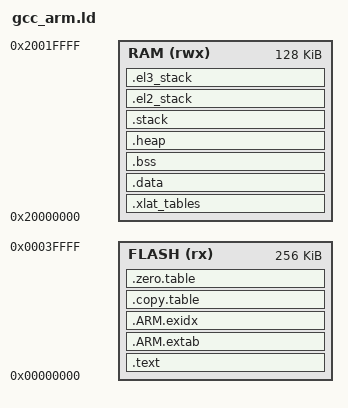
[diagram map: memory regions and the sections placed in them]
/******************************************************************************
 * @file     gcc_arm.ld
 * @brief    GNU Linker Script for Cortex-A based device
 * @version  V1.0.1
 * @date     20. August 2020
 ******************************************************************************/
/*
 * Copyright (c) 2020 Arm Limited. All rights reserved.
 *
 * SPDX-License-Identifier: Apache-2.0
 *
 * Licensed under the Apache License, Version 2.0 (the License); you may
 * not use this file except in compliance with the License.
 * You may obtain a copy of the License at
 *
 * www.apache.org/licenses/LICENSE-2.0
 *
 * Unless required by applicable law or agreed to in writing, software
 * distributed under the License is distributed on an AS IS BASIS, WITHOUT
 * WARRANTIES OR CONDITIONS OF ANY KIND, either express or implied.
 * See the License for the specific language governing permissions and
 * limitations under the License.
 */

/*
 *-------- <<< Use Configuration Wizard in Context Menu >>> -------------------
 */

/*---------------------- Flash Configuration ----------------------------------
  <h> Flash Configuration
    <o0> Flash Base Address <0x0-0xFFFFFFFF:8>
    <o1> Flash Size (in Bytes) <0x0-0xFFFFFFFF:8>
  </h>
  -----------------------------------------------------------------------------*/
__ROM_BASE = 0x00000000;
__ROM_SIZE = 0x00040000;

/*--------------------- Embedded RAM Configuration ----------------------------
  <h> RAM Configuration
    <o0> RAM Base Address    <0x0-0xFFFFFFFF:8>
    <o1> RAM Size (in Bytes) <0x0-0xFFFFFFFF:8>
  </h>
 -----------------------------------------------------------------------------*/
__RAM_BASE = 0x20000000;
__RAM_SIZE = 0x00020000;

/*--------------------- Stack / Heap Configuration ----------------------------
  <h> Stack / Heap Configuration
    <o0> Stack Size (in Bytes) <0x0-0xFFFFFFFF:8>
    <o1> Heap Size (in Bytes) <0x0-0xFFFFFFFF:8>
  </h>
  -----------------------------------------------------------------------------*/
__STACK_SIZE = 0x00004000;
__HEAP_SIZE  = 0x0000C000;

/*--------------------- EL2 Stack Configuration -------------------------------
  <h> EL2 Stack Configuration
    <o0> Stack Size (in Bytes) <0x0-0xFFFFFFFF:8>
  </h>
 -----------------------------------------------------------------------------*/
__EL2_STACK_SIZE = 0x00004000;

/*--------------------- EL3 Stack Configuration -------------------------------
  <h> EL3 Stack Configuration
    <o0> Stack Size (in Bytes) <0x0-0xFFFFFFFF:8>
  </h>
  -----------------------------------------------------------------------------*/
__EL3_STACK_SIZE = 0x00004000;

/*
 *-------------------- <<< end of configuration section >>> -------------------
 */

MEMORY
{
  FLASH (rx)  : ORIGIN = __ROM_BASE, LENGTH = __ROM_SIZE
  RAM   (rwx) : ORIGIN = __RAM_BASE, LENGTH = __RAM_SIZE
}

/* Linker script to place sections and symbol values. Should be used together
 * with other linker script that defines memory regions FLASH and RAM.
 * It references following symbols, which must be defined in code:
 *   Reset_Handler : Entry of reset handler
 *
 * It defines following symbols, which code can use without definition:
 *   __exidx_start
 *   __exidx_end
 *   __copy_table_start__
 *   __copy_table_end__
 *   __zero_table_start__
 *   __zero_table_end__
 *   __etext
 *   __data_start__
 *   __preinit_array_start
 *   __preinit_array_end
 *   __init_array_start
 *   __init_array_end
 *   __fini_array_start
 *   __fini_array_end
 *   __data_end__
 *   __bss_start__
 *   __bss_end__
 *   __end__
 *   end
 *   __HeapLimit
 *   __StackLimit
 *   __StackTop
 *   __stack
 */
ENTRY(Reset_Handler)

SECTIONS
{
  .text :
  {
    KEEP(*(.startup))

    KEEP(*(.vectors))
    *(.text*)

    KEEP(*(.init))
    KEEP(*(.fini))

    /* .ctors */
    *crtbegin.o(.ctors)
    *crtbegin?.o(.ctors)
    *(EXCLUDE_FILE(*crtend?.o *crtend.o) .ctors)
    *(SORT(.ctors.*))
    *(.ctors)

    /* .dtors */
    *crtbegin.o(.dtors)
    *crtbegin?.o(.dtors)
    *(EXCLUDE_FILE(*crtend?.o *crtend.o) .dtors)
    *(SORT(.dtors.*))
    *(.dtors)

    *(.rodata*)
    *(.gcc_except_table*)

    KEEP(*(.eh_frame*))
  } > FLASH

  /*
   * SG veneers:
   * All SG veneers are placed in the special output section .gnu.sgstubs. Its start address
   * must be set, either with the command line option ?--section-start? or in a linker script,
   * to indicate where to place these veneers in memory.
   */
/*
  .gnu.sgstubs :
  {
    . = ALIGN(32);
  } > FLASH
*/

  .ARM.extab :
  {
    *(.ARM.extab* .gnu.linkonce.armextab.*)
  } > FLASH

  __exidx_start = .;
  .ARM.exidx :
  {
    *(.ARM.exidx* .gnu.linkonce.armexidx.*)
  } > FLASH
  __exidx_end = .;

  .copy.table :
  {
    . = ALIGN(8);
    __copy_table_start__ = .;
    LONG (__etext)
    LONG (__data_start__)
    LONG ((__data_end__ - __data_start__) / 4)
    /* Add each additional data section here */
/*
    LONG (__etext2)
    LONG (__data2_start__)
    LONG ((__data2_end__ - __data2_start__) / 4)
*/
    __copy_table_end__ = .;
  } > FLASH

  .zero.table :
  {
    . = ALIGN(8);
    __zero_table_start__ = .;
    /* Add each additional bss section here */
/*
    LONG (__bss2_start__)
    LONG ((__bss2_end__ - __bss2_start__) / 4)
*/
    __zero_table_end__ = .;
  } > FLASH

  .xlat_tables :
  {
    . = ALIGN(4096);
    *(.xlat_tables)
 } > RAM

  __etext = ALIGN (8);

  .data : AT (__etext)
  {
    __data_start__ = .;
    *(vtable)
    *(.data)
    *(.data.*)

    . = ALIGN(8);
    /* preinit data */
    PROVIDE_HIDDEN (__preinit_array_start = .);
    KEEP(*(.preinit_array))
    PROVIDE_HIDDEN (__preinit_array_end = .);

    . = ALIGN(8);
    /* init data */
    PROVIDE_HIDDEN (__init_array_start = .);
    KEEP(*(SORT(.init_array.*)))
    KEEP(*(.init_array))
    PROVIDE_HIDDEN (__init_array_end = .);

    . = ALIGN(8);
    /* finit data */
    PROVIDE_HIDDEN (__fini_array_start = .);
    KEEP(*(SORT(.fini_array.*)))
    KEEP(*(.fini_array))
    PROVIDE_HIDDEN (__fini_array_end = .);

    KEEP(*(.jcr*))
    . = ALIGN(8);
    /* All data end */
    __data_end__ = .;

  } > RAM

  /*
   * Secondary data section, optional
   *
   * Remember to add each additional data section
   * to the .copy.table  and .ecc.table above to asure proper
   * initialization during startup.
   */
/*
  __etext2 = ALIGN (8);

  .data2 : AT (__etext2)
  {
    . = ALIGN(8);
    __data2_start__ = .;
    *(.data2)
    *(.data2.*)
    . = ALIGN(8);
    __data2_end__ = .;
  } > RAM2
*/

  .bss :
  {
    . = ALIGN(8);
    __bss_start__ = .;
    *(.bss)
    *(.bss.*)
    *(COMMON)
    . = ALIGN(8);
    __bss_end__ = .;
  } > RAM AT > RAM

  /*
   * Secondary bss section, optional
   *
   * Remember to add each additional bss section
   * to the .zero.table and .ecc.table above to asure proper
   * initialization during startup.
   */
/*
  .bss2 :
  {
    . = ALIGN(8);
    __bss2_start__ = .;
    *(.bss2)
    *(.bss2.*)
    . = ALIGN(8);
    __bss2_end__ = .;
  } > RAM2 AT > RAM2
*/

  .heap (COPY) :
  {
    . = ALIGN(8);
    __HeapTop = .;
    __end__ = .;
    PROVIDE(end = .);
    . = . + __HEAP_SIZE;
    . = ALIGN(8);
    __HeapLimit = .;
  } > RAM

  .stack (ORIGIN(RAM) + LENGTH(RAM) - __STACK_SIZE - __EL2_STACK_SIZE - __EL3_STACK_SIZE) (COPY) :
  {
    . = ALIGN(8);
    __StackLimit = .;
    . = . + __STACK_SIZE;
    . = ALIGN(8);
    __StackTop = .;
  } > RAM

  /* Set EL2 stack.  */
  .el2_stack (ORIGIN(RAM) + LENGTH(RAM) - __EL2_STACK_SIZE - __EL3_STACK_SIZE) (COPY) :
  {
  . = ALIGN(8);
  __EL2StackLimit = .;
  . = . + __EL2_STACK_SIZE;
  . = ALIGN(8);
  __EL2StackTop = .;
  } > RAM
  
  /* Set EL3 stack.  */
  .el3_stack (ORIGIN(RAM) + LENGTH(RAM) - __EL3_STACK_SIZE) (COPY) :
  {
  . = ALIGN(8);
  __EL3StackLimit = .;
  . = . + __EL3_STACK_SIZE;
  . = ALIGN(8);
  __EL3StackTop = .;
  } > RAM

  PROVIDE(__stack = __StackTop);

  /* Check if data + heap + stack exceeds RAM limit */
  ASSERT(__StackLimit >= __HeapLimit, "region RAM overflowed with stack")
}
